# STM32H757_CM4 register map
File version: 2.3
CPU: CM4 r0p1, little endian, MPU, FPU, 4 interrupt priority bits
Registers are 32-bit, read-write, reset 0x0 unless marked. A register's access mark holds for its fields unless they carry their own. Offsets are from the block's base; [hi:lo] are bit positions; {n}, {i} and the like mark numbered series.

## CRC — Cryptographic processor
Base 0x58024C00
0x00 DR reset 0xFFFFFFFF — Data register
  [31:0] DR — Data Register
0x00 DR8 8-bit reset 0xFF (alternate view of DR) — Data register - byte sized
  [7:0] DR8 — Data register bits
0x00 DR16 16-bit reset 0xFFFF (alternate view of DR) — Data register - half-word sized
  [15:0] DR16 — Data register bits
0x04 IDR — Independent Data register
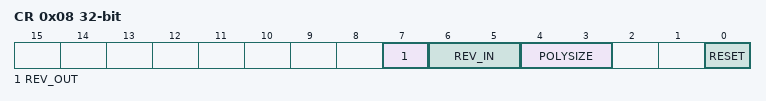
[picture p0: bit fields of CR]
0x08 CR — Control register
  [7] REV_OUT — Reverse output data
    0=Normal (Bit order not affected); 1=Reversed (Bit reversed output)
  [6:5] REV_IN — Reverse input data
    0=Normal (Bit order not affected); 1=Byte (Bit reversal done by byte); 2=HalfWord (Bit reversal done by half-word); 3=Word (Bit reversal done by word)
  [4:3] POLYSIZE — Polynomial size
    0=32-bit polynomial; 1=16-bit polynomial; 2=8-bit polynomial; 3=7-bit polynomial
  [0] RESET — RESET bit
    on write: 1=Resets the CRC calculation unit and sets the data register to 0xFFFF FFFF
0x10 INIT reset 0xFFFFFFFF — Initial CRC value
  [31:0] INIT — Programmable initial CRC value
0x14 POL reset 0x4C11DB7 — CRC polynomial
  [31:0] POL — Programmable polynomial

## DELAY_Block_SDMMC1
Base 0x52008000
Same registers: DELAY_Block_SDMMC2 0x48022800, DELAY_Block_QUADSPI 0x52006000
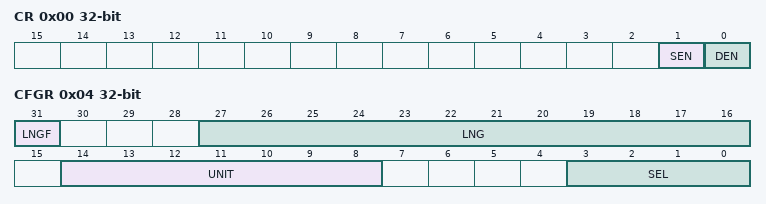
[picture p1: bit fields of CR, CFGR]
0x00 CR — DLYB control register
  [1] SEN — Sampler length enable bit
  [0] DEN — Delay block enable bit
0x04 CFGR — DLYB configuration register
  [31] LNGF — Length valid flag
  [27:16] LNG — Delay line length value
  [14:8] UNIT — Delay Defines the delay of a Unit delay cell
  [3:0] SEL — Select the phase for the Output clock

## HASH — Hash processor
Base 0x48021400
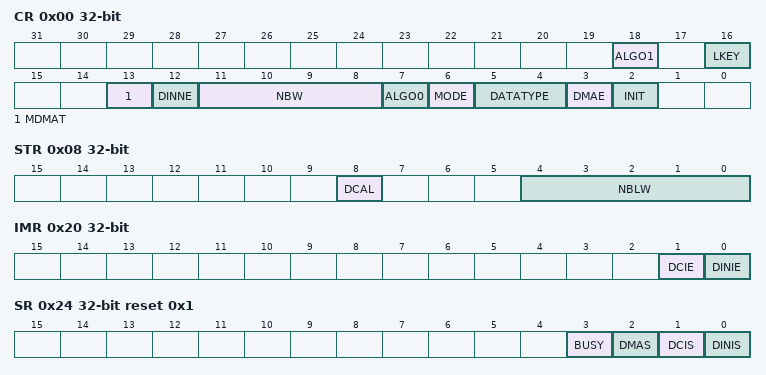
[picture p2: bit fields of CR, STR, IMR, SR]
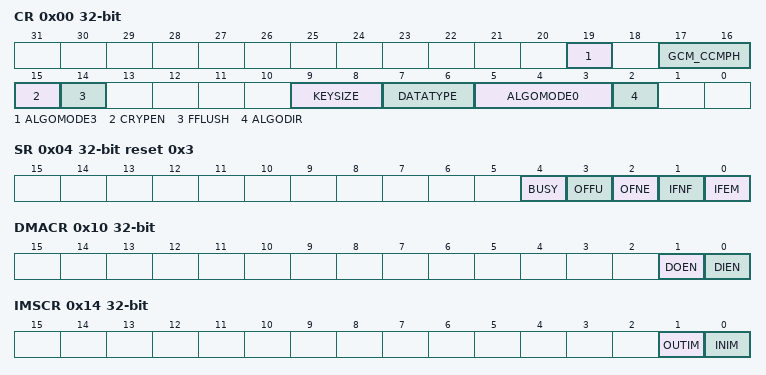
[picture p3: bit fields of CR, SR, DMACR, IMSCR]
0x00 CR access per field — control register
  [18] ALGO1 rw — ALGO
  [16] LKEY rw — Long key selection
  [13] MDMAT rw — Multiple DMA Transfers
  [12] DINNE ro — DIN not empty
  [11:8] NBW ro — Number of words already pushed
  [7] ALGO0 rw — Algorithm selection
  [6] MODE rw — Mode selection
  [5:4] DATATYPE rw — Data type selection
  [3] DMAE rw — DMA enable
  [2] INIT wo — Initialize message digest calculation
0x04 DIN — data input register
  [31:0] DATAIN — Data input
0x08 STR access per field — start register
  [8] DCAL wo — Digest calculation
  [4:0] NBLW rw — Number of valid bits in the last word of the message
{0xC+4i} HR{i} (i=0..4) ro — digest registers
  [31:0] H — H0
0x20 IMR — interrupt enable register
  [1] DCIE — Digest calculation completion interrupt enable
  [0] DINIE — Data input interrupt enable
0x24 SR access per field reset 0x1 — status register
  [3] BUSY ro — Busy bit
  [2] DMAS ro — DMA Status
  [1] DCIS rw — Digest calculation completion interrupt status
  [0] DINIS rw — Data input interrupt status
{0xF8+4i} CSR{i} (i=0..53) — context swap registers
  [31:0] CSR — CSR0
{0x310+4i} HASH_HR{i} (i=0..7) ro — HASH digest register {i}
  [31:0] H — H0

## CRYP — Cryptographic processor
Base 0x48021000
0x00 CR access per field — control register
  [19] ALGOMODE3 rw — ALGOMODE
  [17:16] GCM_CCMPH rw
  [15] CRYPEN rw — Cryptographic processor enable
  [14] FFLUSH wo — FIFO flush
  [9:8] KEYSIZE rw — Key size selection (AES mode only)
  [7:6] DATATYPE rw — Data type selection
  [5:3] ALGOMODE0 rw — Algorithm mode
  [2] ALGODIR rw — Algorithm direction
0x04 SR ro reset 0x3 — status register
  [4] BUSY — Busy bit
  [3] OFFU — Output FIFO full
  [2] OFNE — Output FIFO not empty
  [1] IFNF — Input FIFO not full
  [0] IFEM — Input FIFO empty
0x08 DIN — data input register
  [31:0] DATAIN — Data input
0x0C DOUT ro — data output register
  [31:0] DATAOUT — Data output
0x10 DMACR — DMA control register
  [1] DOEN — DMA output enable
  [0] DIEN — DMA input enable
0x14 IMSCR — interrupt mask set/clear register
  [1] OUTIM — Output FIFO service interrupt mask
  [0] INIM — Input FIFO service interrupt mask
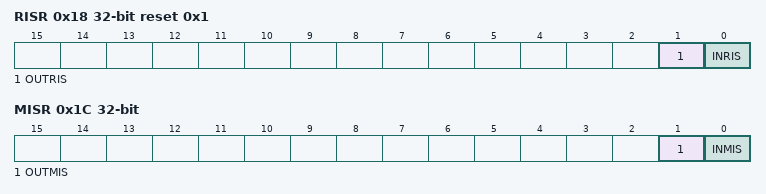
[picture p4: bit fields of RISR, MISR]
0x18 RISR ro reset 0x1 — raw interrupt status register
  [1] OUTRIS — Output FIFO service raw interrupt status
  [0] INRIS — Input FIFO service raw interrupt status
0x1C MISR ro — masked interrupt status register
  [1] OUTMIS — Output FIFO service masked interrupt status
  [0] INMIS — Input FIFO service masked interrupt status
0x20 K0LR wo — key registers
  [31:0] b2 — b224
0x24 K0RR wo — key registers
  [31:0] b — b192
0x28 K1LR wo — key registers
  [31:0] b1 — b160
0x2C K1RR wo — key registers
  [31:0] b1 — b128
0x30 K2LR wo — key registers
  [31:0] b — b96
0x34 K2RR wo — key registers
  [31:0] b — b64
0x38 K3LR wo — key registers
  [31:0] b — b32
0x3C K3RR wo — key registers
  [31:0] b — b0
0x40 IV0LR — initialization vector registers
  [31:0] IV — IV31
0x44 IV0RR — initialization vector registers
  [31:0] IV — IV63
0x48 IV1LR — initialization vector registers
  [31:0] IV — IV95
0x4C IV1RR — initialization vector registers
  [31:0] IV — IV127
{0x50+4i} CSGCMCCM{i}R (i=0..7) — context swap register
{0x70+4i} CSGCM{i}R (i=0..7) — context swap register
